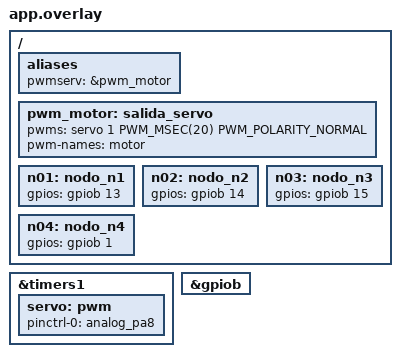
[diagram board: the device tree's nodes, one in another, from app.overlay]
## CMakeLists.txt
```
# SPDX-License-Identifier: Apache-2.0

cmake_minimum_required(VERSION 3.20.0)

find_package(Zephyr REQUIRED HINTS $ENV{ZEPHYR_BASE})
project(hello_world)

target_sources(app PRIVATE src/main.c)
# SPDX-License-Identifier: Apache-2.0

cmake_minimum_required(VERSION 3.20.0)

find_package(Zephyr REQUIRED HINTS $ENV{ZEPHYR_BASE})
project(pwm_musica)

target_sources(app PRIVATE
    src/main.c
)
target_include_directories(app PRIVATE src)
```

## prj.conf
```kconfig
# Added automatically by Workbench for Zephyr
#--- DEBUG PRESET - BEGIN ---#
# Set to -Og
CONFIG_DEBUG_OPTIMIZATIONS=y
# Thread awareness support
CONFIG_DEBUG_THREAD_INFO=y
# Generate stack usage per-function
CONFIG_STACK_USAGE=y
# Other options in case not set by default
CONFIG_BUILD_OUTPUT_HEX=y
CONFIG_BUILD_OUTPUT_META=y
CONFIG_OUTPUT_SYMBOLS=y
CONFIG_OUTPUT_STAT=y
CONFIG_OUTPUT_DISASSEMBLY=y
CONFIG_OUTPUT_PRINT_MEMORY_USAGE=y

CONFIG_GPIO=y
#--- DEBUG PRESET - END ---#
```

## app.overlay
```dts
#include <zephyr/dt-bindings/pwm/pwm.h>
#include <zephyr/dt-bindings/pwm/stm32_pwm.h>
#include <zephyr/dt-bindings/pinctrl/stm32-pinctrl.h>
#include <zephyr/dt-bindings/timer/stm32-timer.h>
#include <zephyr/dt-bindings/gpio/gpio.h>

/ {
    aliases {
        pwmserv = &pwm_motor;
    };
    pwm_motor: salida_servo {
        pwms = <&servo 1 PWM_MSEC(20) PWM_POLARITY_NORMAL>;
        pwm-names = "motor";
    };

    /* GPIO N1 */
    n01: nodo_n1 {
        gpios = <&gpiob 13 GPIO_ACTIVE_HIGH>;
    };

    /* GPIO N2 */
    n02: nodo_n2 {
        gpios = <&gpiob 14 GPIO_ACTIVE_HIGH>;
    };

    /* GPIO N3 */
    n03: nodo_n3 {
        gpios = <&gpiob 15 GPIO_ACTIVE_HIGH>;
    };

    /* GPIO N4 */
    n04: nodo_n4 {
        gpios = <&gpiob 1 GPIO_ACTIVE_HIGH>;
    };
};

/* DEVICETREE-MANAGER-BEGIN: generated region, do not edit inside this block */
&timers1 {
    status = "okay";

    servo: pwm {
        pinctrl-0 = <&analog_pa8>;
        pinctrl-names = "default";
    };
};

&gpiob {
    status = "okay";
};
/* DEVICETREE-MANAGER-END */
```

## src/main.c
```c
/*
 * Copyright (c) 2012-2014 Wind River Systems, Inc.
 *
 * SPDX-License-Identifier: Apache-2.0
 */
#include <zephyr/kernel.h>
#include <zephyr/device.h>
#include <zephyr/drivers/gpio.h>
#include <zephyr/drivers/pwm.h>
#include <stdio.h>

static const struct gpio_dt_spec N1 =
    GPIO_DT_SPEC_GET(DT_NODELABEL(n01), gpios);
```
